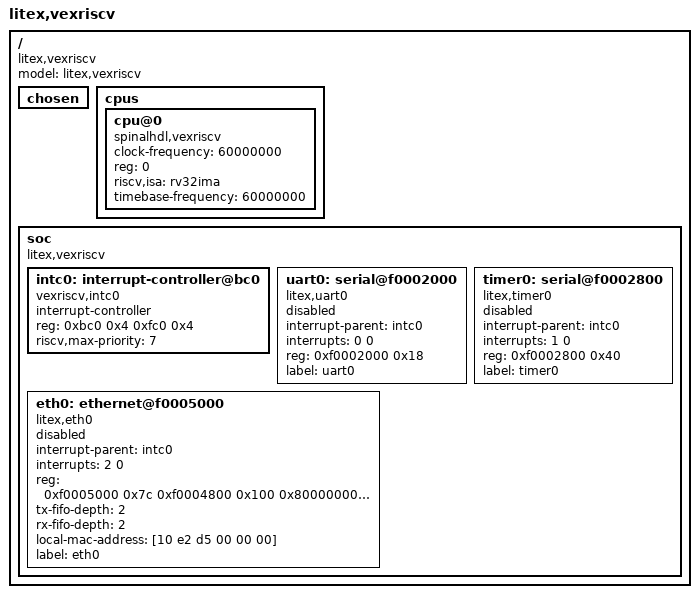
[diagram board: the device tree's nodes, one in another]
/*
 * Copyright (c) 2018 - 2020 Antmicro <www.antmicro.com>
 *
 * SPDX-License-Identifier: Apache-2.0
 */

/ {
	#address-cells = <1>;
	#size-cells = <1>;
	compatible = "litex,vexriscv", "litex-dev";
	model = "litex,vexriscv";


	chosen {
	};

	cpus {
		#address-cells = <1>;
		#size-cells = <0>;
		cpu@0 {
			clock-frequency = <60000000>;
			compatible = "spinalhdl,vexriscv", "riscv";
			device_type = "cpu";
			reg = <0>;
			riscv,isa = "rv32ima";
			status = "okay";
			timebase-frequency = <60000000>;
		};
	};
	soc {
		#address-cells = <1>;
		#size-cells = <1>;
		compatible = "litex,vexriscv";
		ranges;
		intc0: interrupt-controller@bc0 {
			#interrupt-cells = <2>;
			compatible = "vexriscv,intc0";
			interrupt-controller;
			reg = <0xbc0 0x4 0xfc0 0x4>;
			reg-names = "irq_mask", "irq_pending";
			riscv,max-priority = <7>;
		};
		uart0: serial@f0002000 {
			compatible = "litex,uart0";
			interrupt-parent = <&intc0>;
			interrupts = <0 0>;
			reg = <0xf0002000 0x18>;
			reg-names = "control";
			label = "uart0";
			status = "disabled";
		};
		timer0: serial@f0002800 {
			compatible = "litex,timer0";
			interrupt-parent = <&intc0>;
			interrupts = <1 0>;
			reg = <0xf0002800 0x40>;
			reg-names = "control";
			label = "timer0";
			status = "disabled";
		};
		eth0: ethernet@f0005000 {
			compatible = "litex,eth0";
			interrupt-parent = <&intc0>;
			interrupts = <2 0>;
			reg = <0xf0005000 0x7c
			       0xf0004800 0x100
			       0x80000000 0x4000>;
			tx-fifo-depth = <2>;
			rx-fifo-depth = <2>;
			local-mac-address = [10 e2 d5 00 00 00];
			reg-names = "control", "phy", "buffers";
			label = "eth0";
			status = "disabled";
		};
	};
};
